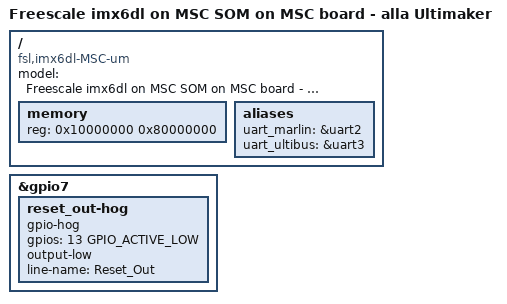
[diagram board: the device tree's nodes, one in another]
/dts-v1/;
#define IMX6DL_ULTIMAKER 1
#include "imx6dl-pinfunc.h"
#include "imx6dl.dtsi"
#include "msc-sm2-imx6sdl.dtsi"
#include "next-ultimainboard3.1.dtsi"
#include "part201258-ulticontroller3.dtsi"
// following largely irrelevant and - in its curretn form -  requires PWM3 available:
// #include "part1994-ulticontroller.dtsi"

/ {
	model = "Freescale imx6dl on MSC SOM on MSC board - alla Ultimaker";
	compatible = "fsl,imx6dl-MSC-um", "fsl,imx6dl";
	memory: memory {
		reg = <0x10000000 0x80000000>; /* 2 GiB */
	};
#if 0
    /* beeper stuff below not woreking - we must stay off pwm3 whose pins are used  for SPI nRST! */
      beeper {
	  pwm-names = "opinicus-board-beeper";
	  compatible = "pwm-beeper";
	  pwms = <&pwm3 1 500000 0>;
	  status = "okay";
      };
#endif

    aliases {
        uart_marlin = &uart2;
        uart_ultibus = &uart3;
    };
};

/*
    This is the Reset_Out# pin from the SOM and it is used to let the carrier board knows when the system is out of 
    reset. So, if needed, it can be used to also reset other onboard devices. In Ultimainboard 4.2 we use this line 
    to reset the GPIO's expanders and the Atmega2560. 
    Formerly this pin was controlled in UBoot (set high before booting the linux kernel) but it was removed by MSC. 
    Then we moved this set to the device tree as a hog pin, so the gpio driver will take control of it during the boot
    setting it to the level we want (in this case, high, since it is active low pin). Although the config below says
    "output-low", this means the logical state of the pin. So an Active_Low pin in the state low (inactive) means a
    pin at high voltage level.
*/
&gpio7 {
    reset_out-hog {
        gpio-hog;
        gpios = <13 GPIO_ACTIVE_LOW>;
        output-low;         //  "Output"-low in an Active_Low pin means high voltage level
        line-name = "Reset_Out";
    };
};
